# f2838x_sys_status_regs register map
Vendor: Texas Instruments
Peripheral module from a debugger description file (folder C2000).
Address unit: 16 bits
Registers are 32-bit, read-write, no defined reset value unless marked. A register's access mark holds for its fields unless they carry their own. Offsets are as the file gives them; lines under a group give offsets from that group; [hi:lo] are bit positions; {n}, {i} and the like mark numbered series; 'fields as' and 'values as' point back to an identical list; <NAME> marks a mode.

## SYS_STATUS_REGS — SYS STATUS Registers
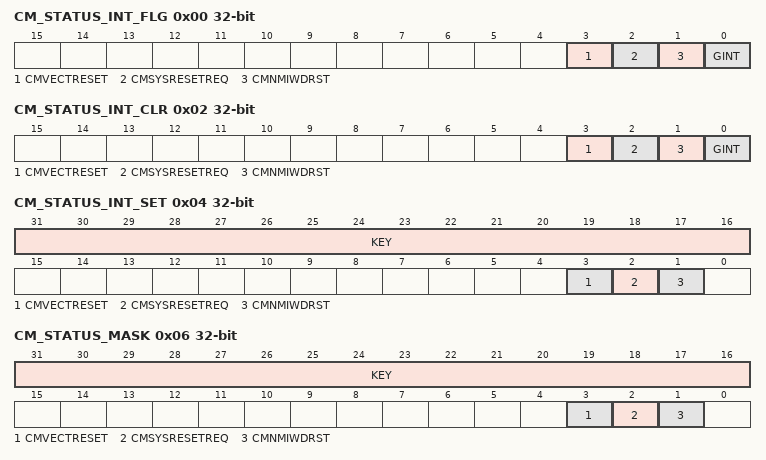
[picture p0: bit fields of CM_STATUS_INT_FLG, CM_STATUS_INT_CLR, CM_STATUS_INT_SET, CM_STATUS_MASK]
0x00 CM_STATUS_INT_FLG ro — Status of interrupts due to multiple sources of Cortex-M4 reset.
  [3] CMVECTRESET — CMVECTRESET caused a reset of CM
  [2] CMSYSRESETREQ — CMSYSRESETREQ caused a reset of CM
  [1] CMNMIWDRST — CMNMIWDRST caused a reset of CM
  [0] GINT — Global Interrupt flag
0x02 CM_STATUS_INT_CLR — CM_STATUS_INT_FLG clear register
  [3] CMVECTRESET — CMVECTRESET interrupt flag clear bit
  [2] CMSYSRESETREQ — CMSYSRESETREQ interrupt flag clear bit
  [1] CMNMIWDRST — CMNMIWDRST interrupt flag clear bit
  [0] GINT — Global Interrupt flag Clear bit
0x04 CM_STATUS_INT_SET — CM_STATUS_INT_FLG set register
  [31:16] KEY
  [3] CMVECTRESET — CMVECTRESET interrupt flag set bit
  [2] CMSYSRESETREQ — CMSYSRESETREQ interrupt flag set bit
  [1] CMNMIWDRST — CMNMIWDRST interrupt flag set bit
0x06 CM_STATUS_MASK
  [31:16] KEY
  [3] CMVECTRESET — CMVECTRESET interrupt flag set bit
  [2] CMSYSRESETREQ — CMSYSRESETREQ interrupt flag set bit
  [1] CMNMIWDRST — CMNMIWDRST flag mask bit
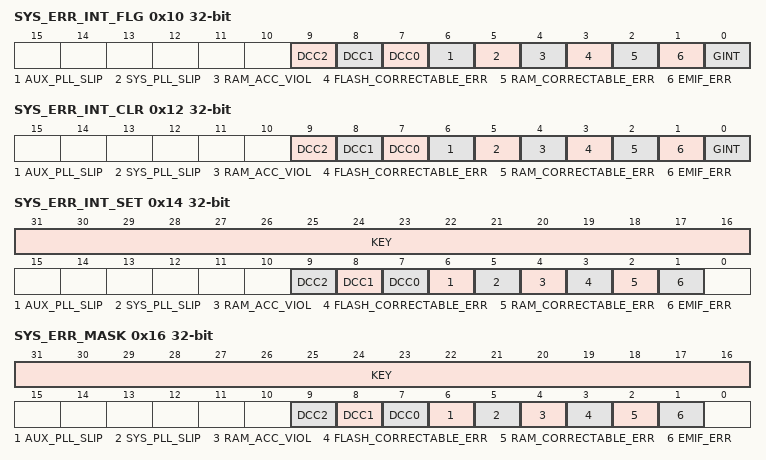
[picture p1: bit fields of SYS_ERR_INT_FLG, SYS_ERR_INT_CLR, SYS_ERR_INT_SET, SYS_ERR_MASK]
0x10 SYS_ERR_INT_FLG ro — Status of interrupts due to multiple different errors in the system.
  [9] DCC2 — DCC2 Interrupt flag.
  [8] DCC1 — DCC1 Interrupt flag.
  [7] DCC0 — DCC0 Interrupt flag.
  [6] AUX_PLL_SLIP — Auxillary PLL Slip event flag.
  [5] SYS_PLL_SLIP — System PLL Slip event flag.
  [4] RAM_ACC_VIOL — A RAM access vioation flag.
  [3] FLASH_CORRECTABLE_ERR — FLASH correctable error flag
  [2] RAM_CORRECTABLE_ERR — RAM correctable error flag
  [1] EMIF_ERR — EMIF error event flag
  [0] GINT — Global Interrupt flag
0x12 SYS_ERR_INT_CLR — SYS_ERR_INT_FLG clear register
  [9] DCC2 — DCC2 interrupt flag clear bit
  [8] DCC1 — DCC1 interrupt flag clear bit
  [7] DCC0 — DCC0 interrupt flag clear bit
  [6] AUX_PLL_SLIP — AUX_PLL_SLIP interrupt flag clear bit
  [5] SYS_PLL_SLIP — SYS_PLL_SLIP interrupt flag clear bit
  [4] RAM_ACC_VIOL — RAM_ACC_VIOL interrupt flag clear bit
  [3] FLASH_CORRECTABLE_ERR — FLASH_CORRECTABLE_ERR interrupt flag clear bit
  [2] RAM_CORRECTABLE_ERR — RAM_CORRECTABLE_ERR interrupt flag clear bit
  [1] EMIF_ERR — EMIF_ERR interrupt flag clear bit
  [0] GINT — Global Interrupt flag Clear bit
0x14 SYS_ERR_INT_SET — SYS_ERR_INT_FLG set register
  [31:16] KEY
  [9] DCC2 — DCC2 interrupt flag set bit
  [8] DCC1 — DCC1 interrupt flag set bit
  [7] DCC0 — DCC0 interrupt flag set bit
  [6] AUX_PLL_SLIP — AUX_PLL_SLIP interrupt flag set bit
  [5] SYS_PLL_SLIP — SYS_PLL_SLIP interrupt flag set bit
  [4] RAM_ACC_VIOL — RAM_ACC_VIOL interrupt flag set bit
  [3] FLASH_CORRECTABLE_ERR — FLASH_CORRECTABLE_ERR interrupt flag set bit
  [2] RAM_CORRECTABLE_ERR — RAM_CORRECTABLE_ERR interrupt flag set bit
  [1] EMIF_ERR — Reserved
0x16 SYS_ERR_MASK
  [31:16] KEY
  [9] DCC2 — DCC2 flag mask bit
  [8] DCC1 — DCC1 flag mask bit
  [7] DCC0 — DCC0 flag mask bit
  [6] AUX_PLL_SLIP — AUX_PLL_SLIP flag mask bit
  [5] SYS_PLL_SLIP — SYS_PLL_SLIP flag mask bit
  [4] RAM_ACC_VIOL — RAM_ACC_VIOL flag mask bit
  [3] FLASH_CORRECTABLE_ERR — FLASH_CORRECTABLE_ERR flag mask bit
  [2] RAM_CORRECTABLE_ERR — RAM_CORRECTABLE_ERR flag mask bit
  [1] EMIF_ERR — Reserved
